# S32K148_M4 register map
Vendor: NXP Semiconductors; File version: 1.0
CPU: CM4 r0p1, little endian, MPU, FPU, VTOR, 4 interrupt priority bits
Registers are 32-bit, read-write, reset 0x0 unless marked. A register's access mark holds for its fields unless they carry their own. Offsets are from the block's base; [hi:lo] are bit positions; {n}, {i} and the like mark numbered series; 'fields as' and 'values as' point back to an identical list.

## SCG — System Clock Generator
Base 0x40064000; register names take the prefix SCG_
0x00 VERID ro reset 0x1000000 — Version ID Register
  [31:0] VERSION — SCG Version Number
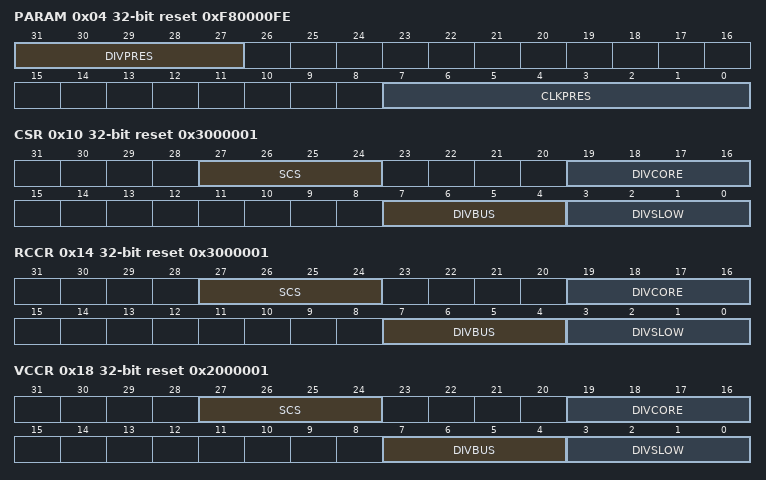
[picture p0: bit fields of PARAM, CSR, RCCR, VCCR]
0x04 PARAM ro reset 0xF80000FE — Parameter Register
  [31:27] DIVPRES — Divider Present
  [7:0] CLKPRES — Clock Present
0x10 CSR ro reset 0x3000001 — Clock Status Register
  [27:24] SCS — System Clock Source
    1=System OSC (SOSC_CLK); 2=Slow IRC (SIRC_CLK); 3=Fast IRC (FIRC_CLK); 6=System PLL (SPLL_CLK)
  [19:16] DIVCORE — Core Clock Divide Ratio
    {v}=Divide-by-{v+1} (v=0..15)
  [7:4] DIVBUS — Bus Clock Divide Ratio
    {v}=Divide-by-{v+1} (v=0..15)
  [3:0] DIVSLOW — Slow Clock Divide Ratio
    {v}=Divide-by-{v+1} (v=0..7)
0x14 RCCR reset 0x3000001 — Run Clock Control Register
  fields as CSR
0x18 VCCR reset 0x2000001 — VLPR Clock Control Register
  [27:24] SCS — System Clock Source
    2=Slow IRC (SIRC_CLK)
  [19:16] DIVCORE — Core Clock Divide Ratio
    {v}=Divide-by-{v+1} (v=0..15)
  [7:4] DIVBUS — Bus Clock Divide Ratio
    {v}=Divide-by-{v+1} (v=0..15)
  [3:0] DIVSLOW — Slow Clock Divide Ratio
    {v}=Divide-by-{v+1} (v=0..7)
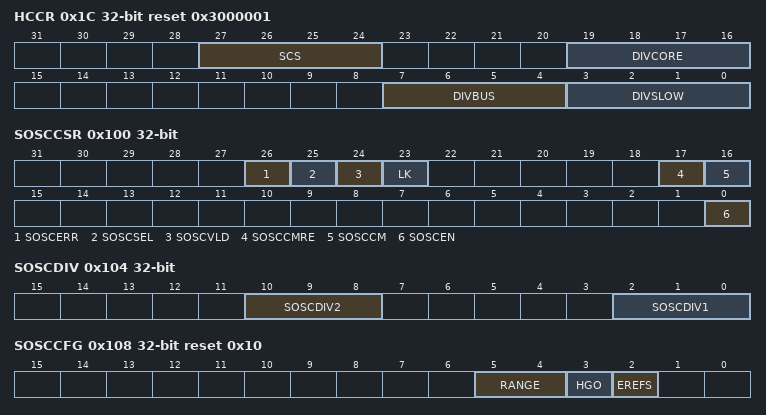
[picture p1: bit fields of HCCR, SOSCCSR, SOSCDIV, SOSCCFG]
0x1C HCCR reset 0x3000001 — HSRUN Clock Control Register
  [27:24] SCS — System Clock Source
    3=Fast IRC (FIRC_CLK); 6=System PLL (SPLL_CLK)
  [19:16] DIVCORE — Core Clock Divide Ratio
    {v}=Divide-by-{v+1} (v=0..15)
  [7:4] DIVBUS — Bus Clock Divide Ratio
    {v}=Divide-by-{v+1} (v=0..15)
  [3:0] DIVSLOW — Slow Clock Divide Ratio
    {v}=Divide-by-{v+1} (v=0..7)
0x20 CLKOUTCNFG reset 0x3000000 — SCG CLKOUT Configuration Register
  [27:24] CLKOUTSEL — SCG Clkout Select
    0=SCG SLOW Clock; 1=System OSC (SOSC_CLK); 2=Slow IRC (SIRC_CLK); 3=Fast IRC (FIRC_CLK); 6=System PLL (SPLL_CLK)
0x100 SOSCCSR — System OSC Control Status Register
  [26] SOSCERR write-1-clears — System OSC Clock Error
    0=System OSC Clock Monitor is disabled or has not detected an error; 1=System OSC Clock Monitor is enabled and detected an error
  [25] SOSCSEL ro — System OSC Selected
    0=System OSC is not the system clock source; 1=System OSC is the system clock source
  [24] SOSCVLD ro — System OSC Valid
    0=System OSC is not enabled or clock is not valid; 1=System OSC is enabled and output clock is valid
  [23] LK — Lock Register
    0=This Control Status Register can be written; 1=This Control Status Register cannot be written
  [17] SOSCCMRE — System OSC Clock Monitor Reset Enable
    0=Clock Monitor generates interrupt when error detected; 1=Clock Monitor generates reset when error detected
  [16] SOSCCM — System OSC Clock Monitor
    0=System OSC Clock Monitor is disabled; 1=System OSC Clock Monitor is enabled
  [0] SOSCEN — System OSC Enable
    0=System OSC is disabled; 1=System OSC is enabled
0x104 SOSCDIV — System OSC Divide Register
  [10:8] SOSCDIV2 — System OSC Clock Divide 2
    0=Output disabled; 1=Divide by 1; 2=Divide by 2; 3=Divide by 4; 4=Divide by 8; 5=Divide by 16; 6=Divide by 32; 7=Divide by 64
  [2:0] SOSCDIV1 — System OSC Clock Divide 1
    values as SOSCDIV2
0x108 SOSCCFG reset 0x10 — System Oscillator Configuration Register
  [5:4] RANGE — System OSC Range Select
    1=Low frequency range selected for the crystal oscillator; 2=Medium frequency range selected for the crytstal oscillator; 3=High frequency range selected for the crystal oscillator
  [3] HGO — High Gain Oscillator Select
    0=Configure crystal oscillator for low-gain operation; 1=Configure crystal oscillator for high-gain operation
  [2] EREFS — External Reference Select
    0=External reference clock selected; 1=Internal crystal oscillator of OSC selected
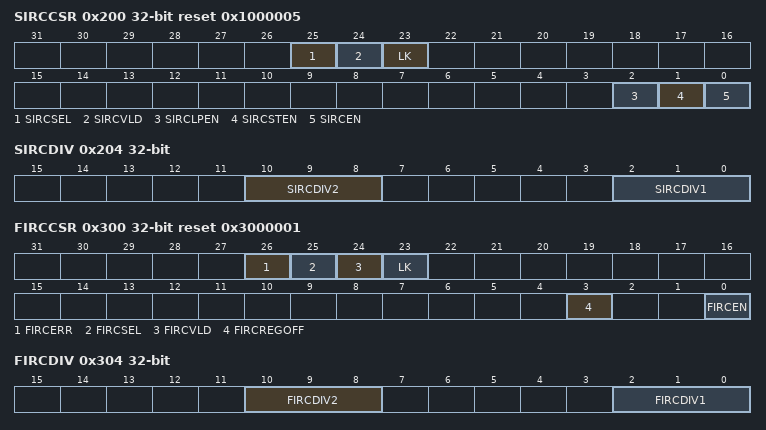
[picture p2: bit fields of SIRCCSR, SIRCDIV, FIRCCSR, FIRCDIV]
0x200 SIRCCSR reset 0x1000005 — Slow IRC Control Status Register
  [25] SIRCSEL ro — Slow IRC Selected
    0=Slow IRC is not the system clock source; 1=Slow IRC is the system clock source
  [24] SIRCVLD ro — Slow IRC Valid
    0=Slow IRC is not enabled or clock is not valid; 1=Slow IRC is enabled and output clock is valid
  [23] LK — Lock Register
    0=Control Status Register can be written; 1=Control Status Register cannot be written
  [2] SIRCLPEN — Slow IRC Low Power Enable
    0=Slow IRC is disabled in VLP modes; 1=Slow IRC is enabled in VLP modes
  [1] SIRCSTEN — Slow IRC Stop Enable
    0=Slow IRC is disabled in supported Stop modes; 1=Slow IRC is enabled in supported Stop modes
  [0] SIRCEN — Slow IRC Enable
    0=Slow IRC is disabled; 1=Slow IRC is enabled
0x204 SIRCDIV — Slow IRC Divide Register
  [10:8] SIRCDIV2 — Slow IRC Clock Divide 2
    values as SOSCDIV.SOSCDIV2
  [2:0] SIRCDIV1 — Slow IRC Clock Divide 1
    values as SOSCDIV.SOSCDIV2
0x208 SIRCCFG reset 0x1 — Slow IRC Configuration Register
  [0] RANGE — Frequency Range
    0=Slow IRC low range clock (2 MHz); 1=Slow IRC high range clock (8 MHz )
0x300 FIRCCSR reset 0x3000001 — Fast IRC Control Status Register
  [26] FIRCERR write-1-clears — Fast IRC Clock Error
    0=Error not detected with the Fast IRC trimming; 1=Error detected with the Fast IRC trimming
  [25] FIRCSEL ro — Fast IRC Selected status
    0=Fast IRC is not the system clock source; 1=Fast IRC is the system clock source
  [24] FIRCVLD ro — Fast IRC Valid status
    0=Fast IRC is not enabled or clock is not valid; 1=Fast IRC is enabled and output clock is valid. The clock is valid once there is an output clock from the FIRC analog.
  [23] LK — Lock Register
    values as SIRCCSR.LK
  [3] FIRCREGOFF — Fast IRC Regulator Enable
    0=Fast IRC Regulator is enabled; 1=Fast IRC Regulator is disabled
  [0] FIRCEN — Fast IRC Enable
    0=Fast IRC is disabled; 1=Fast IRC is enabled
0x304 FIRCDIV — Fast IRC Divide Register
  [10:8] FIRCDIV2 — Fast IRC Clock Divide 2
    values as SOSCDIV.SOSCDIV2
  [2:0] FIRCDIV1 — Fast IRC Clock Divide 1
    values as SOSCDIV.SOSCDIV2
0x308 FIRCCFG — Fast IRC Configuration Register
  [1:0] RANGE — Frequency Range
    0=Fast IRC is trimmed to 48 MHz
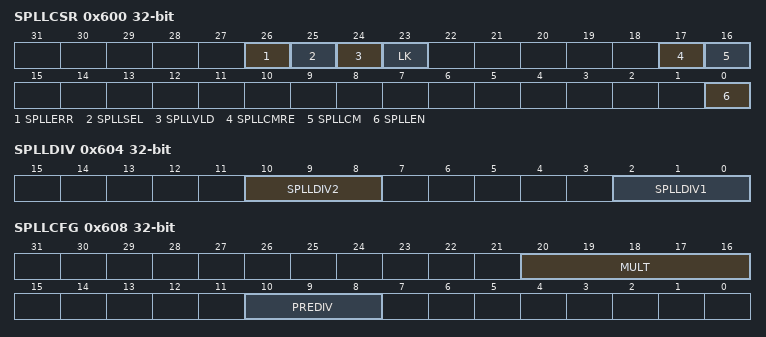
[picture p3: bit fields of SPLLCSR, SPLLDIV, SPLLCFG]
0x600 SPLLCSR — System PLL Control Status Register
  [26] SPLLERR write-1-clears — System PLL Clock Error
    0=System PLL Clock Monitor is disabled or has not detected an error; 1=System PLL Clock Monitor is enabled and detected an error. System PLL Clock Error flag will not set when System OSC is selected as its source and SOSCERR has set.
  [25] SPLLSEL ro — System PLL Selected
    0=System PLL is not the system clock source; 1=System PLL is the system clock source
  [24] SPLLVLD ro — System PLL Valid
    0=System PLL is not enabled or clock is not valid; 1=System PLL is enabled and output clock is valid
  [23] LK — Lock Register
    values as SIRCCSR.LK
  [17] SPLLCMRE — System PLL Clock Monitor Reset Enable
    values as SOSCCSR.SOSCCMRE
  [16] SPLLCM — System PLL Clock Monitor
    0=System PLL Clock Monitor is disabled; 1=System PLL Clock Monitor is enabled
  [0] SPLLEN — System PLL Enable
    0=System PLL is disabled; 1=System PLL is enabled
0x604 SPLLDIV — System PLL Divide Register
  [10:8] SPLLDIV2 — System PLL Clock Divide 2
    0=Clock disabled; 1=Divide by 1; 2=Divide by 2; 3=Divide by 4; 4=Divide by 8; 5=Divide by 16; 6=Divide by 32; 7=Divide by 64
  [2:0] SPLLDIV1 — System PLL Clock Divide 1
    values as SPLLDIV2
0x608 SPLLCFG — System PLL Configuration Register
  [20:16] MULT — System PLL Multiplier
  [10:8] PREDIV — PLL Reference Clock Divider

## Notices in the file
Copyright 2016-2021 NXP
NXP Confidential. This software is owned or controlled by NXP and may only be
used strictly in accordance with the applicable license terms. By expressly
accepting such terms or by downloading, installing, activating and/or otherwise
using the software, you are agreeing that you have read, and that you agree to
comply with and are bound by, such license terms. If you do not agree to be
bound by the applicable license terms, then you may not retain, install,
activate or otherwise use the software. The production use license in
Section 2.3 is expressly granted for this software.
